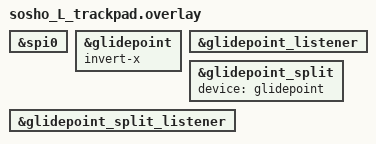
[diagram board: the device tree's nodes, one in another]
#include "sosho_L.dtsi"

&spi0 { status = "okay"; };
&glidepoint {
    status = "okay";
    invert-x;
};
&glidepoint_listener {
    status = "okay";
/* input-processors = <&zip_xy_scaler 3 1>; */
};

&glidepoint_split {
    status = "okay";
    device = <&glidepoint>;
};
&glidepoint_split_listener {
    status = "okay";
/* input-processors = <&zip_xy_scaler 3 1>; */
};
